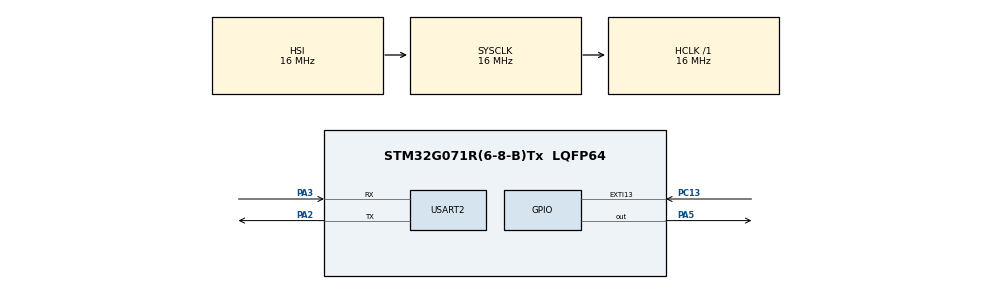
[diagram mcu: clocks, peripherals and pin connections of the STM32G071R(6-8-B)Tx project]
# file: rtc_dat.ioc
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Mcu.Family=STM32G0
Mcu.Name=STM32G071R(6-8-B)Tx
Mcu.Package=LQFP64
NVIC.EXTI4_15_IRQn=true\:0\:0\:false\:true\:true\:1\:true\:true
PA2.Mode=Asynchronous
PA2.Signal=USART2_TX
PA3.Mode=Asynchronous
PA3.Signal=USART2_RX
PA5.Signal=GPIO_Output
PC13.Signal=GPXTI13
PC14-OSC32_IN\ (PC14).Mode=LSE-External-Oscillator
PC14-OSC32_IN\ (PC14).Signal=RCC_OSC32_IN
PC15-OSC32_OUT\ (PC15).Mode=LSE-External-Oscillator
PC15-OSC32_OUT\ (PC15).Signal=RCC_OSC32_OUT
ProjectManager.HeapSize=0x200
ProjectManager.StackSize=0x400
ProjectManager.TargetToolchain=STM32CubeIDE
RCC.AHBFreq_Value=16000000
RCC.CortexFreq_Value=16000000
RCC.EXTERNAL_CLOCK_VALUE=48000
RCC.HCLKFreq_Value=16000000
RCC.HSE_VALUE=8000000
RCC.HSI_VALUE=16000000
RCC.RTCClockSelection=RCC_RTCCLKSOURCE_LSE
RCC.SYSCLKFreq_VALUE=16000000
RCC.VCOOutputFreq_Value=128000000
RTC.HourFormat=RTC_HOURFORMAT_12
RTC.Year=19
USART2.VirtualMode-Asynchronous=VM_ASYNC
USART2.WordLength=WORDLENGTH_8B
VP_RTC_VS_RTC_Activate.Mode=RTC_Enabled
VP_RTC_VS_RTC_Calendar.Mode=RTC_Calendar
VP_SYS_VS_DBSignals.Mode=DisableDeadBatterySignals
board=custom

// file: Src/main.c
/* USER CODE BEGIN Header */
/**
  ******************************************************************************
  * @file           : main.c
  * @brief          : Main program body
  ******************************************************************************
  * @attention
  *
  * <h2><center>&copy; Copyright (c) 2019 STMicroelectronics.
  * All rights reserved.</center></h2>
  *
  * This software component is licensed by ST under BSD 3-Clause license,
  * the "License"; You may not use this file except in compliance with the
  * License. You may obtain a copy of the License at:
  *                        opensource.org/licenses/BSD-3-Clause
  *
  ******************************************************************************
  */
/* USER CODE END Header */

#include "main.h"
#include "stdio.h"
#include "string.h"

RTC_HandleTypeDef hrtc;

UART_HandleTypeDef huart2;

RTC_TimeTypeDef sTime = {0};
RTC_DateTypeDef sDate = {0};

void SystemClock_Config(void);
static void MX_GPIO_Init(void);
static void MX_RTC_Init(void);
static void MX_USART2_UART_Init(void);
static void MX_NVIC_Init(void);

int main(void)
{

  /* MCU Configuration--------------------------------------------------------*/

  /* Reset of all peripherals, Initializes the Flash interface and the Systick. */
  HAL_Init();

  /* Configure the system clock */
  SystemClock_Config();

  /* Initialize all configured peripherals */
  MX_GPIO_Init();
  MX_RTC_Init();
  MX_USART2_UART_Init();

  /* Initialize interrupts */
  MX_NVIC_Init();

  /* Infinite loop */
  while (1)
  {

  }
}

void SystemClock_Config(void)
{
  RCC_OscInitTypeDef RCC_OscInitStruct = {0};
  RCC_ClkInitTypeDef RCC_ClkInitStruct = {0};
  RCC_PeriphCLKInitTypeDef PeriphClkInit = {0};

  /** Configure the main internal regulator output voltage
  */
  HAL_PWREx_ControlVoltageScaling(PWR_REGULATOR_VOLTAGE_SCALE1);
  /** Configure LSE Drive Capability
  */
  __HAL_RCC_LSEDRIVE_CONFIG(RCC_LSEDRIVE_LOW);
  /** Initializes the CPU, AHB and APB busses clocks
  */
  RCC_OscInitStruct.OscillatorType = RCC_OSCILLATORTYPE_HSI|RCC_OSCILLATORTYPE_LSE;
  RCC_OscInitStruct.LSEState = RCC_LSE_ON;
  RCC_OscInitStruct.HSIState = RCC_HSI_ON;
  RCC_OscInitStruct.HSIDiv = RCC_HSI_DIV1;
  RCC_OscInitStruct.HSICalibrationValue = RCC_HSICALIBRATION_DEFAULT;
  RCC_OscInitStruct.PLL.PLLState = RCC_PLL_NONE;
  if (HAL_RCC_OscConfig(&RCC_OscInitStruct) != HAL_OK)
  {
    Error_Handler();
  }
  /** Initializes the CPU, AHB and APB busses clocks
  */
  RCC_ClkInitStruct.ClockType = RCC_CLOCKTYPE_HCLK|RCC_CLOCKTYPE_SYSCLK
                              |RCC_CLOCKTYPE_PCLK1;
  RCC_ClkInitStruct.SYSCLKSource = RCC_SYSCLKSOURCE_HSI;
  RCC_ClkInitStruct.AHBCLKDivider = RCC_SYSCLK_DIV1;
  RCC_ClkInitStruct.APB1CLKDivider = RCC_HCLK_DIV1;

  if (HAL_RCC_ClockConfig(&RCC_ClkInitStruct, FLASH_LATENCY_0) != HAL_OK)
  {
    Error_Handler();
  }
  /** Initializes the peripherals clocks
  */
  PeriphClkInit.PeriphClockSelection = RCC_PERIPHCLK_RTC|RCC_PERIPHCLK_USART2;
  PeriphClkInit.Usart2ClockSelection = RCC_USART2CLKSOURCE_PCLK1;
  PeriphClkInit.RTCClockSelection = RCC_RTCCLKSOURCE_LSE;

  if (HAL_RCCEx_PeriphCLKConfig(&PeriphClkInit) != HAL_OK)
  {
    Error_Handler();
  }
}

/**
  * @brief NVIC Configuration.
  * @retval None
  */
static void MX_NVIC_Init(void)
{
  /* EXTI4_15_IRQn interrupt configuration */
  HAL_NVIC_SetPriority(EXTI4_15_IRQn, 0, 0);
  HAL_NVIC_EnableIRQ(EXTI4_15_IRQn);
}

static void MX_RTC_Init(void)
{

  /** Initialize RTC Only
  */
  hrtc.Instance = RTC;
  hrtc.Init.HourFormat = RTC_HOURFORMAT_24;
  hrtc.Init.AsynchPrediv = 127;
  hrtc.Init.SynchPrediv = 255;
  hrtc.Init.OutPut = RTC_OUTPUT_DISABLE;
  hrtc.Init.OutPutRemap = RTC_OUTPUT_REMAP_NONE;
  hrtc.Init.OutPutPolarity = RTC_OUTPUT_POLARITY_HIGH;
  hrtc.Init.OutPutType = RTC_OUTPUT_TYPE_OPENDRAIN;
  hrtc.Init.OutPutPullUp = RTC_OUTPUT_PULLUP_NONE;
  if (HAL_RTC_Init(&hrtc) != HAL_OK)
  {
    Error_Handler();
  }

  /** Initialize RTC and set the Time and Date
  */
  sTime.Hours = 0x13;
  sTime.Minutes = 0x59;
  sTime.Seconds = 0x40;
  sTime.SubSeconds = 0x0;
  sTime.TimeFormat = RTC_HOURFORMAT12_AM;
  sTime.DayLightSaving = RTC_DAYLIGHTSAVING_NONE;
  sTime.StoreOperation = RTC_STOREOPERATION_RESET;
  if (HAL_RTC_SetTime(&hrtc, &sTime, RTC_FORMAT_BCD) != HAL_OK)
  {
    Error_Handler();
  }
  sDate.WeekDay = RTC_WEEKDAY_MONDAY;
  sDate.Month = RTC_MONTH_JANUARY;
  sDate.Date = 0x1;
  sDate.Year = 0x19;

  if (HAL_RTC_SetDate(&hrtc, &sDate, RTC_FORMAT_BCD) != HAL_OK)
  {
    Error_Handler();
  }

}

static void MX_USART2_UART_Init(void)
{

  huart2.Instance = USART2;
  huart2.Init.BaudRate = 115200;
  huart2.Init.WordLength = UART_WORDLENGTH_8B;
  huart2.Init.StopBits = UART_STOPBITS_1;
  huart2.Init.Parity = UART_PARITY_NONE;
  huart2.Init.Mode = UART_MODE_TX_RX;
  huart2.Init.HwFlowCtl = UART_HWCONTROL_NONE;
  huart2.Init.OverSampling = UART_OVERSAMPLING_16;
  huart2.Init.OneBitSampling = UART_ONE_BIT_SAMPLE_DISABLE;
  huart2.Init.ClockPrescaler = UART_PRESCALER_DIV1;
  huart2.AdvancedInit.AdvFeatureInit = UART_ADVFEATURE_NO_INIT;
  if (HAL_UART_Init(&huart2) != HAL_OK)
  {
    Error_Handler();
  }
  if (HAL_UARTEx_SetTxFifoThreshold(&huart2, UART_TXFIFO_THRESHOLD_1_8) != HAL_OK)
  {
    Error_Handler();
  }
  if (HAL_UARTEx_SetRxFifoThreshold(&huart2, UART_RXFIFO_THRESHOLD_1_8) != HAL_OK)
  {
    Error_Handler();
  }
  if (HAL_UARTEx_DisableFifoMode(&huart2) != HAL_OK)
  {
    Error_Handler();
  }

}

static void MX_GPIO_Init(void)
{
  GPIO_InitTypeDef GPIO_InitStruct = {0};

  /* GPIO Ports Clock Enable */
  __HAL_RCC_GPIOC_CLK_ENABLE();
  __HAL_RCC_GPIOA_CLK_ENABLE();

  /*Configure GPIO pin Output Level */
  HAL_GPIO_WritePin(GPIOA, GPIO_PIN_5, GPIO_PIN_RESET);

  /*Configure GPIO pin : PC13 */
  GPIO_InitStruct.Pin = GPIO_PIN_13;
  GPIO_InitStruct.Mode = GPIO_MODE_IT_RISING;
  GPIO_InitStruct.Pull = GPIO_NOPULL;
  HAL_GPIO_Init(GPIOC, &GPIO_InitStruct);

  /*Configure GPIO pin : PA5 */
  GPIO_InitStruct.Pin = GPIO_PIN_5;
  GPIO_InitStruct.Mode = GPIO_MODE_OUTPUT_PP;
  GPIO_InitStruct.Pull = GPIO_NOPULL;
  GPIO_InitStruct.Speed = GPIO_SPEED_FREQ_LOW;
  HAL_GPIO_Init(GPIOA, &GPIO_InitStruct);

}

/* USER CODE BEGIN 4 */
void HAL_GPIO_EXTI_Rising_Callback(uint16_t GPIO_Pin)
{
HAL_RTC_GetTime(&hrtc,&sTime, RTC_FORMAT_BIN);
HAL_RTC_GetDate(&hrtc,&sDate, RTC_FORMAT_BIN);
char msg[50];
sprintf(msg,"date=%d-%d-%d,time=%d-%d-%d",sDate.Date,sDate.Month,sDate.Year,sTime.Hours,sTime.Minutes,sTime.Seconds);
HAL_UART_Transmit(&huart2, (uint8_t *)msg, strlen((const char*)msg), 1000);

}
/* USER CODE END 4 */

void Error_Handler(void)
{
}

/************************ (C) COPYRIGHT STMicroelectronics *****END OF FILE****/
